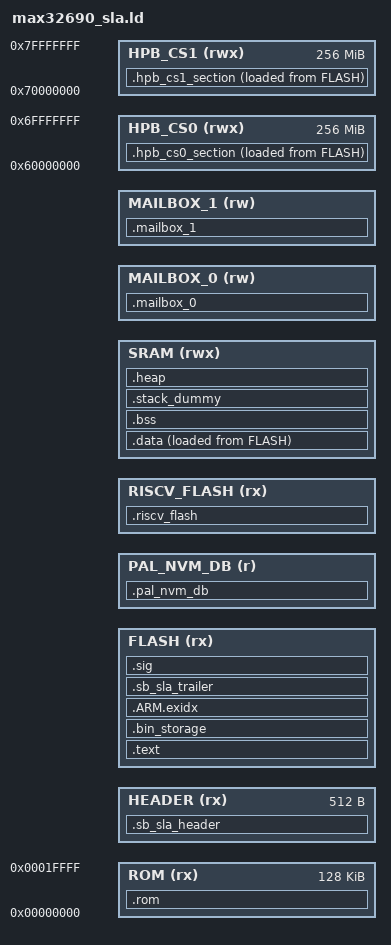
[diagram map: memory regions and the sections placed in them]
/******************************************************************************
 *
 * Copyright (C) 2022-2023 Maxim Integrated Products, Inc. (now owned by 
 * Analog Devices, Inc.),
 * Copyright (C) 2023-2024 Analog Devices, Inc.
 *
 * Licensed under the Apache License, Version 2.0 (the "License");
 * you may not use this file except in compliance with the License.
 * You may obtain a copy of the License at
 *
 *     http://www.apache.org/licenses/LICENSE-2.0
 *
 * Unless required by applicable law or agreed to in writing, software
 * distributed under the License is distributed on an "AS IS" BASIS,
 * WITHOUT WARRANTIES OR CONDITIONS OF ANY KIND, either express or implied.
 * See the License for the specific language governing permissions and
 * limitations under the License.
 *
 ******************************************************************************/
ARM_SLA_HEADER_ORIGIN = _FLASH_ORIGIN;
ARM_SLA_HEADER_SIZE = 0x200;

ARM_FLASH_ORIGIN = ARM_SLA_HEADER_ORIGIN + ARM_SLA_HEADER_SIZE;
ARM_FLASH_SIZE = _FLASH_SIZE - _RISCV_FLASH_SIZE - _PAL_NVM_SIZE - ARM_SLA_HEADER_SIZE;

PAL_NVM_ORIGIN = _FLASH_SIZE - _PAL_NVM_SIZE + _FLASH_ORIGIN;

RISCV_FLASH_ORIGIN = _RISCV_FLASH_ORIGIN;
RISCV_FLASH_SIZE = _RISCV_FLASH_SIZE;

ARM_SRAM_ORIGIN = _SRAM_ORIGIN;
ARM_SRAM_SIZE = _SRAM_SIZE - _RISCV_SRAM_SIZE;

MAILBOX_ORIGIN = _RISCV_SRAM_ORIGIN;

RISCV_SRAM_ORIGIN = _RISCV_SRAM_ORIGIN;
RISCV_SRAM_SIZE = _RISCV_SRAM_SIZE;

MEMORY {    
    ROM        (rx) : ORIGIN = 0x00000000,    LENGTH = 0x00020000 /* 128kB ROM */
    HEADER     (rx) : ORIGIN = ARM_SLA_HEADER_ORIGIN,    LENGTH = ARM_SLA_HEADER_SIZE
    FLASH      (rx) : ORIGIN = ARM_FLASH_ORIGIN,    LENGTH = ARM_FLASH_SIZE
    PAL_NVM_DB (r)  : ORIGIN = PAL_NVM_ORIGIN,      LENGTH = _PAL_NVM_SIZE
    RISCV_FLASH(rx) : ORIGIN = RISCV_FLASH_ORIGIN,  LENGTH = RISCV_FLASH_SIZE
    SRAM      (rwx) : ORIGIN = ARM_SRAM_ORIGIN,    LENGTH = ARM_SRAM_SIZE
    MAILBOX_0  (rw) : ORIGIN = MAILBOX_ORIGIN,      LENGTH = _MAILBOX_SIZE
    MAILBOX_1  (rw) : ORIGIN = MAILBOX_ORIGIN + _MAILBOX_SIZE, LENGTH = _MAILBOX_SIZE
	
	/*
     * Note that CS0/CS1 address mappings may be reversed using MXC_HPC->mbr0 and ->mbr1
     * The following mappings are selected for simplicity
     */
    HPB_CS0 (rwx)  : ORIGIN = 0x60000000, LENGTH = 0x10000000  /* External Hyperbus/Xccelabus chip select 0 */
    HPB_CS1 (rwx)  : ORIGIN = 0x70000000, LENGTH = 0x10000000  /* External Hyperbus/Xccelabus chip select 1 */
	
}

ENTRY(Reset_Handler)
PROVIDE( _start_SWAP = (((Reset_Handler) >> 24) | (((Reset_Handler) & 0x00FF0000) >> 8) | (((Reset_Handler) & 0x0000FF00) << 8) | ((Reset_Handler) << 24)));
PROVIDE_HIDDEN( _SLA_Size = _endimage - __end_header );
PROVIDE( _SLA_Size_SWAP = (((_SLA_Size) >> 24) | (((_SLA_Size) & 0x00FF0000) >> 8) | (((_SLA_Size) & 0x0000FF00) << 8) | ((_SLA_Size) << 24)));

SECTIONS {
    .rom :
    {
        KEEP(*(.rom_vector))
        *(.rom_handlers*)
    } > ROM

     .sb_sla_header : ALIGN(4)
    {
       FILL(0xFF)
        KEEP(*(.sb_sla_header)) /* Header for ROM code */ 
         __end_header = . ;
        . = ALIGN(512);
    } > HEADER
    
    .text :
    {
        _text = .;
        KEEP(*(.isr_vector))
        EXCLUDE_FILE (*riscv.o) *(.text*)    /* program code, exclude RISCV code */
        *(.rodata*)  /* read-only data: "const" */

        KEEP(*(.init))
        KEEP(*(.fini))

        /* C++ Exception handling */
        KEEP(*(.eh_frame*))
        _etext = .;
    } > FLASH

    /* These sections allow code to be compiled/linked for HPB addresses, but reside in
     * flash until copied by code to the external HPB flash device
     */
    .hpb_cs0_section :
    {
	__hpb_cs0_start = ABSOLUTE(.);
        KEEP(*(.hpb_cs0_section*))
    } > HPB_CS0 AT>FLASH

    __load_start_hpb_cs0 = LOADADDR(.hpb_cs0_section);
    __load_length_hpb_cs0 = SIZEOF(.hpb_cs0_section);

    .hpb_cs1_section :
    {
    	__hpb_cs1_start = ABSOLUTE(.);
        KEEP(*(.hpb_cs1_section*))
    } > HPB_CS1 AT>FLASH

    __load_start_hpb_cs1 = LOADADDR(.hpb_cs1_section);
    __load_length_hpb_cs1 = SIZEOF(.hpb_cs1_section);
	
    /* Binary import */
    .bin_storage :
    {
       FILL(0xFF)
      _bin_start_ = .;
      KEEP(*(.bin_storage_img))
      _bin_end_ = .;
      . = ALIGN(4);
    } > FLASH

    /* it's used for C++ exception handling      */
    /* we need to keep this to avoid overlapping */
    .ARM.exidx :
    {
        __exidx_start = .;
        *(.ARM.exidx*)
        __exidx_end = .;
    } > FLASH

    .data :
    {
        _data = ALIGN(., 4);
        *(.data*)           /*read-write initialized data: initialized global variable*/

        /* These array sections are used by __libc_init_array to call static C++ constructors */
        . = ALIGN(4);
        /* preinit data */
        PROVIDE_HIDDEN (__preinit_array_start = .);
        KEEP(*(.preinit_array))
        PROVIDE_HIDDEN (__preinit_array_end = .);

        . = ALIGN(4);
        /* init data */
        PROVIDE_HIDDEN (__init_array_start = .);
        KEEP(*(SORT(.init_array.*)))
        KEEP(*(.init_array))
        PROVIDE_HIDDEN (__init_array_end = .);

        . = ALIGN(4);
        /* finit data */
        PROVIDE_HIDDEN (__fini_array_start = .);
        KEEP(*(SORT(.fini_array.*)))
        KEEP(*(.fini_array))
        PROVIDE_HIDDEN (__fini_array_end = .);

        /* Run the flash programming functions from SRAM */
        *(.flashprog)

        _edata = ALIGN(., 4);
    } > SRAM AT>FLASH
    __load_data = LOADADDR(.data);
    _enddata = LOADADDR(.data)+SIZEOF(.data);
    
    .sb_sla_trailer : AT(_enddata)
    {
        KEEP(*(.sb_sla_trailer))
        /* Align image with 16 byte boundary to conform to flash encryption block size. */
        FILL(0xDEADC0DE);
        /* NOTE: The FILL and ALIGN will not work unless something is written to the section.  So, we use LONG. */
        LONG(0xDEADC0DE);
        . = ALIGN(16);
    }  > FLASH
    _endimage = LOADADDR(.sb_sla_trailer)+SIZEOF(.sb_sla_trailer);
    .sig :
    {
        KEEP(*(.sig))
        LONG(0xDEADBEEF);

    }  > FLASH
    
    .bss :
    {
        . = ALIGN(4);
        _bss = .;
        *(.bss*)     /*read-write zero initialized data: uninitialzed global variable*/
        *(COMMON)
        _ebss = ALIGN(., 4);
    } > SRAM

    .pal_nvm_db :
    {
    /* Align to the sector size */
    . = ALIGN(0x2000);
    __pal_nvm_db_start__ = .;
    . = . + _PAL_NVM_SIZE;
    __pal_nvm_db_end__ = .;
    } > PAL_NVM_DB

    .riscv_flash :
    {
        KEEP(*riscv.o) /* RISCV program code */
    } > RISCV_FLASH

    /* Set stack top to end of RAM, and stack limit move down by
     * size of stack_dummy section */
    __StackTop = ORIGIN(SRAM) + LENGTH(SRAM);
    __StackLimit = __StackTop - SIZEOF(.stack_dummy);

    /* .stack_dummy section doesn't contains any symbols. It is only
     * used for linker to calculate size of stack sections, and assign
     * values to stack symbols later */
    .stack_dummy (COPY):
    {
        *(.stack*)
    } > SRAM

    .heap (COPY):
    {
        . = ALIGN(4);
        *(.heap*)
        __HeapLimit = ABSOLUTE(__StackLimit);
    } > SRAM

    .mailbox_0 (NOLOAD) :
    {
        _mailbox_0 = ALIGN(., 4); 
        *(.mailbox_0*)           /*Shared memory section*/
        . = . + _MAILBOX_SIZE;
        _emailbox_0 = ALIGN(., 4);
    } > MAILBOX_0

    .mailbox_1 (NOLOAD) :
    {
        _mailbox_1 = ALIGN(., 4);
        *(.mailbox_1*)           /*Shared memory section*/
        . = . + _MAILBOX_SIZE;
        _emailbox_1 = ALIGN(., 4);
    } > MAILBOX_1

    PROVIDE(__stack = __StackTop);

    /* Check if data + heap + stack exceeds RAM limit */
    ASSERT(__StackLimit >= _ebss, "region RAM overflowed with stack")
}
